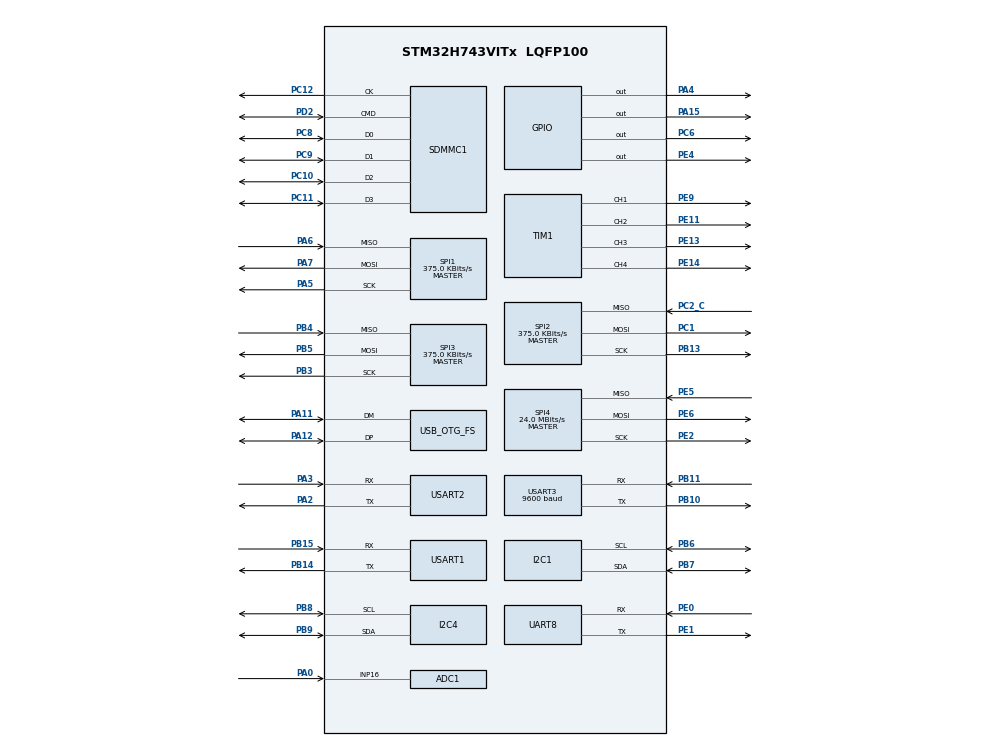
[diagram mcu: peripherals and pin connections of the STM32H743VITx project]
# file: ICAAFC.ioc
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ADC1.Channel-0\#ChannelRegularConversion=ADC_CHANNEL_16
ADC1.ContinuousConvMode=ENABLE
ADC1.ConversionDataManagement=ADC_CONVERSIONDATA_DMA_CIRCULAR
ADC1.NbrOfConversionFlag=1
ADC1.OffsetNumber-0\#ChannelRegularConversion=ADC_OFFSET_NONE
ADC1.OffsetSignedSaturation-0\#ChannelRegularConversion=DISABLE
ADC1.Rank-0\#ChannelRegularConversion=1
ADC1.SamplingTime-0\#ChannelRegularConversion=ADC_SAMPLETIME_32CYCLES_5
ADC1.master=1
CORTEX_M7.default_mode_Activation=1
Dma.ADC1.0.Direction=DMA_PERIPH_TO_MEMORY
Dma.ADC1.0.EventEnable=DISABLE
Dma.ADC1.0.FIFOMode=DMA_FIFOMODE_DISABLE
Dma.ADC1.0.Instance=DMA1_Stream0
Dma.ADC1.0.MemDataAlignment=DMA_MDATAALIGN_HALFWORD
Dma.ADC1.0.MemInc=DMA_MINC_ENABLE
Dma.ADC1.0.Mode=DMA_CIRCULAR
Dma.ADC1.0.PeriphDataAlignment=DMA_PDATAALIGN_HALFWORD
Dma.ADC1.0.PeriphInc=DMA_PINC_DISABLE
Dma.ADC1.0.Polarity=HAL_DMAMUX_REQ_GEN_RISING
Dma.ADC1.0.Priority=DMA_PRIORITY_LOW
Dma.ADC1.0.RequestNumber=1
Dma.ADC1.0.SignalID=NONE
Dma.ADC1.0.SyncEnable=DISABLE
Dma.ADC1.0.SyncPolarity=HAL_DMAMUX_SYNC_NO_EVENT
Dma.ADC1.0.SyncRequestNumber=1
Dma.ADC1.0.SyncSignalID=NONE
Dma.Request0=ADC1
FREERTOS.Tasks01=HeartTask,24,256,AppHeartTask,Default,NULL,Dynamic,NULL,NULL;CommunicateTask,8,256,AppCommunicateTask02,Default,NULL,Dynamic,NULL,NULL;ControllerTask,8,256,AppControllerTask,Default,NULL,Dynamic,NULL,NULL;NavigationTask,8,256,AppNavigationTask,Default,NULL,Dynamic,NULL,NULL;EstimatorTask,8,256,AppEstimatorTask,Default,NULL,Dynamic,NULL,NULL
I2C1.Timing=0x20303E5D
I2C4.Timing=0x20303E5D
Mcu.Family=STM32H7
Mcu.Name=STM32H743VITx
Mcu.Package=LQFP100
NVIC.DMA1_Stream0_IRQn=true\:5\:0\:false\:false\:true\:true\:false\:true\:true
NVIC.PriorityGroup=NVIC_PRIORITYGROUP_4
NVIC.TIM6_DAC_IRQn=true\:15\:0\:false\:false\:true\:false\:false\:true\:true
NVIC.TimeBase=TIM6_DAC_IRQn
NVIC.TimeBaseIP=TIM6
NVIC.USART2_IRQn=true\:5\:0\:false\:false\:true\:true\:true\:true\:true
NVIC.USART3_IRQn=true\:5\:0\:false\:false\:true\:true\:true\:true\:true
PA0.Mode=IN16-Single-Ended
PA0.Signal=ADC1_INP16
PA11.Mode=Device_Only
PA11.Signal=USB_OTG_FS_DM
PA12.Mode=Device_Only
PA12.Signal=USB_OTG_FS_DP
PA13\ (JTMS/SWDIO).Mode=Serial_Wire
PA13\ (JTMS/SWDIO).Signal=DEBUG_JTMS-SWDIO
PA14\ (JTCK/SWCLK).Mode=Serial_Wire
PA14\ (JTCK/SWCLK).Signal=DEBUG_JTCK-SWCLK
PA15\ (JTDI).Signal=GPIO_Output
PA2.Mode=Asynchronous
PA2.Signal=USART2_TX
PA3.Mode=Asynchronous
PA3.Signal=USART2_RX
PA4.Signal=GPIO_Output
PA5.Mode=Full_Duplex_Master
PA5.Signal=SPI1_SCK
PA6.Mode=Full_Duplex_Master
PA6.Signal=SPI1_MISO
PA7.Mode=Full_Duplex_Master
PA7.Signal=SPI1_MOSI
PB10.Mode=Asynchronous
PB10.Signal=USART3_TX
PB11.Mode=Asynchronous
PB11.Signal=USART3_RX
PB13.Mode=Full_Duplex_Master
PB13.Signal=SPI2_SCK
PB14.Mode=Asynchronous
PB14.Signal=USART1_TX
PB15.Mode=Asynchronous
PB15.Signal=USART1_RX
PB3\ (JTDO/TRACESWO).Mode=Full_Duplex_Master
PB3\ (JTDO/TRACESWO).Signal=SPI3_SCK
PB4\ (NJTRST).Mode=Full_Duplex_Master
PB4\ (NJTRST).Signal=SPI3_MISO
PB5.Mode=Full_Duplex_Master
PB5.Signal=SPI3_MOSI
PB6.Mode=I2C
PB6.Signal=I2C1_SCL
PB7.Mode=I2C
PB7.Signal=I2C1_SDA
PB8.Mode=I2C
PB8.Signal=I2C4_SCL
PB9.Mode=I2C
PB9.Signal=I2C4_SDA
PC1.Mode=Full_Duplex_Master
PC1.Signal=SPI2_MOSI
PC10.Mode=SD_4_bits_Wide_bus
PC10.Signal=SDMMC1_D2
PC11.Mode=SD_4_bits_Wide_bus
PC11.Signal=SDMMC1_D3
PC12.Mode=SD_4_bits_Wide_bus
PC12.Signal=SDMMC1_CK
PC2_C.Mode=Full_Duplex_Master
PC2_C.Signal=SPI2_MISO
PC6.Signal=GPIO_Output
PC8.Mode=SD_4_bits_Wide_bus
PC8.Signal=SDMMC1_D0
PC9.Mode=SD_4_bits_Wide_bus
PC9.Signal=SDMMC1_D1
PD2.Mode=SD_4_bits_Wide_bus
PD2.Signal=SDMMC1_CMD
PE0.Mode=Asynchronous
PE0.Signal=UART8_RX
PE1.Mode=Asynchronous
PE1.Signal=UART8_TX
PE11.Signal=S_TIM1_CH2
PE13.Signal=S_TIM1_CH3
PE14.Signal=S_TIM1_CH4
PE2.Mode=Full_Duplex_Master
PE2.Signal=SPI4_SCK
PE4.Signal=GPIO_Output
PE5.Mode=Full_Duplex_Master
PE5.Signal=SPI4_MISO
PE6.Mode=Full_Duplex_Master
PE6.Signal=SPI4_MOSI
PE9.Signal=S_TIM1_CH1
PH0-OSC_IN\ (PH0).Mode=HSE-External-Oscillator
PH0-OSC_IN\ (PH0).Signal=RCC_OSC_IN
PH1-OSC_OUT\ (PH1).Mode=HSE-External-Oscillator
PH1-OSC_OUT\ (PH1).Signal=RCC_OSC_OUT
ProjectManager.HeapSize=0x200
ProjectManager.StackSize=0x400
ProjectManager.TargetToolchain=MDK-ARM V5.32
RCC.ADCFreq_Value=75000000
RCC.APB1Freq_Value=48000000
RCC.APB2Freq_Value=48000000
RCC.APB3Freq_Value=96000000
RCC.APB4Freq_Value=48000000
RCC.CortexFreq_Value=96000000
RCC.D2PPRE1=RCC_APB1_DIV2
RCC.D2PPRE2=RCC_APB2_DIV2
RCC.D3PPRE=RCC_APB4_DIV2
RCC.DIVM1=1
RCC.DIVM2=1
RCC.DIVN1=24
RCC.DIVN2=18
RCC.DIVQ1=4
RCC.HCLKFreq_Value=96000000
RCC.HSE_VALUE=8000000
RCC.PLL2FRACN=6144
RCC.PLL3FRACN=0
RCC.PLLFRACN=0
RCC.PLLSourceVirtual=RCC_PLLSOURCE_HSE
RCC.SYSCLKFreq_VALUE=96000000
RCC.SYSCLKSource=RCC_SYSCLKSOURCE_PLLCLK
RCC.USBFreq_Value=48000000
SH.S_TIM1_CH1.0=TIM1_CH1,PWM Generation1 CH1
SH.S_TIM1_CH2.0=TIM1_CH2,PWM Generation2 CH2
SH.S_TIM1_CH3.0=TIM1_CH3,PWM Generation3 CH3
SH.S_TIM1_CH4.0=TIM1_CH4,PWM Generation4 CH4
SPI1.BaudRatePrescaler=SPI_BAUDRATEPRESCALER_128
SPI1.CalculateBaudRate=375.0 KBits/s
SPI1.Direction=SPI_DIRECTION_2LINES
SPI1.Mode=SPI_MODE_MASTER
SPI1.VirtualType=VM_MASTER
SPI2.BaudRatePrescaler=SPI_BAUDRATEPRESCALER_128
SPI2.CalculateBaudRate=375.0 KBits/s
SPI2.Direction=SPI_DIRECTION_2LINES
SPI2.Mode=SPI_MODE_MASTER
SPI2.VirtualType=VM_MASTER
SPI3.BaudRatePrescaler=SPI_BAUDRATEPRESCALER_128
SPI3.CalculateBaudRate=375.0 KBits/s
SPI3.Direction=SPI_DIRECTION_2LINES
SPI3.Mode=SPI_MODE_MASTER
SPI3.VirtualType=VM_MASTER
SPI4.CalculateBaudRate=24.0 MBits/s
SPI4.Direction=SPI_DIRECTION_2LINES
SPI4.Mode=SPI_MODE_MASTER
SPI4.VirtualType=VM_MASTER
TIM1.Channel-PWM\ Generation1\ CH1=TIM_CHANNEL_1
TIM1.Channel-PWM\ Generation2\ CH2=TIM_CHANNEL_2
TIM1.Channel-PWM\ Generation3\ CH3=TIM_CHANNEL_3
TIM1.Channel-PWM\ Generation4\ CH4=TIM_CHANNEL_4
USART1.VirtualMode-Asynchronous=VM_ASYNC
USART2.VirtualMode-Asynchronous=VM_ASYNC
USART3.BaudRate=9600
USART3.VirtualMode-Asynchronous=VM_ASYNC
USB_OTG_FS.VirtualMode=Device_Only
VP_FREERTOS_VS_CMSIS_V2.Mode=CMSIS_V2
VP_SYS_VS_tim6.Mode=TIM6
VP_TIM1_VS_ClockSourceINT.Mode=Internal
board=custom

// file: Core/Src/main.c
/* USER CODE BEGIN Header */
/**
  ******************************************************************************
  * @file           : main.c
  * @brief          : Main program body
  ******************************************************************************
  * @attention
  *
  * Copyright (c) 2025 STMicroelectronics.
  * All rights reserved.
  *
  * This software is licensed under terms that can be found in the LICENSE file
  * in the root directory of this software component.
  * If no LICENSE file comes with this software, it is provided AS-IS.
  *
  ******************************************************************************
  */
/* USER CODE END Header */
#include "main.h"
#include "cmsis_os.h"
#include "adc.h"
#include "dma.h"
#include "i2c.h"
#include "sdmmc.h"
#include "spi.h"
#include "tim.h"
#include "usart.h"
#include "usb_otg.h"
#include "gpio.h"

void SystemClock_Config(void);
static void MPU_Config(void);
void MX_FREERTOS_Init(void);

int main(void)
{

  /* MPU Configuration--------------------------------------------------------*/
  MPU_Config();

  /* MCU Configuration--------------------------------------------------------*/

  /* Reset of all peripherals, Initializes the Flash interface and the Systick. */
  HAL_Init();

  /* Configure the system clock */
  SystemClock_Config();

  /* Initialize all configured peripherals */
  MX_GPIO_Init();
  MX_DMA_Init();
  MX_ADC1_Init();
  MX_I2C1_Init();
  MX_I2C4_Init();
  MX_SDMMC1_SD_Init();
  MX_SPI1_Init();
  MX_SPI2_Init();
  MX_SPI3_Init();
  MX_SPI4_Init();
  MX_TIM1_Init();
  MX_UART8_Init();
  MX_USART1_UART_Init();
  MX_USART2_UART_Init();
  MX_USART3_UART_Init();
  MX_USB_OTG_FS_PCD_Init();
  /* USER CODE BEGIN 2 */
/*ujik */
  /* USER CODE END 2 */

  /* Init scheduler */
  osKernelInitialize();

  /* Call init function for freertos objects (in cmsis_os2.c) */
  MX_FREERTOS_Init();

  /* Start scheduler */
  osKernelStart();

  /* We should never get here as control is now taken by the scheduler */

  /* Infinite loop */
  while (1)
  {

  }
}

void SystemClock_Config(void)
{
  RCC_OscInitTypeDef RCC_OscInitStruct = {0};
  RCC_ClkInitTypeDef RCC_ClkInitStruct = {0};

  /** Supply configuration update enable
  */
  HAL_PWREx_ConfigSupply(PWR_LDO_SUPPLY);

  /** Configure the main internal regulator output voltage
  */
  __HAL_PWR_VOLTAGESCALING_CONFIG(PWR_REGULATOR_VOLTAGE_SCALE3);

  while(!__HAL_PWR_GET_FLAG(PWR_FLAG_VOSRDY)) {}

  /** Initializes the RCC Oscillators according to the specified parameters
  * in the RCC_OscInitTypeDef structure.
  */
  RCC_OscInitStruct.OscillatorType = RCC_OSCILLATORTYPE_HSE;
  RCC_OscInitStruct.HSEState = RCC_HSE_ON;
  RCC_OscInitStruct.PLL.PLLState = RCC_PLL_ON;
  RCC_OscInitStruct.PLL.PLLSource = RCC_PLLSOURCE_HSE;
  RCC_OscInitStruct.PLL.PLLM = 1;
  RCC_OscInitStruct.PLL.PLLN = 24;
  RCC_OscInitStruct.PLL.PLLP = 2;
  RCC_OscInitStruct.PLL.PLLQ = 4;
  RCC_OscInitStruct.PLL.PLLR = 2;
  RCC_OscInitStruct.PLL.PLLRGE = RCC_PLL1VCIRANGE_3;
  RCC_OscInitStruct.PLL.PLLVCOSEL = RCC_PLL1VCOWIDE;
  RCC_OscInitStruct.PLL.PLLFRACN = 0;
  if (HAL_RCC_OscConfig(&RCC_OscInitStruct) != HAL_OK)
  {
    Error_Handler();
  }

  /** Initializes the CPU, AHB and APB buses clocks
  */
  RCC_ClkInitStruct.ClockType = RCC_CLOCKTYPE_HCLK|RCC_CLOCKTYPE_SYSCLK
                              |RCC_CLOCKTYPE_PCLK1|RCC_CLOCKTYPE_PCLK2
                              |RCC_CLOCKTYPE_D3PCLK1|RCC_CLOCKTYPE_D1PCLK1;
  RCC_ClkInitStruct.SYSCLKSource = RCC_SYSCLKSOURCE_PLLCLK;
  RCC_ClkInitStruct.SYSCLKDivider = RCC_SYSCLK_DIV1;
  RCC_ClkInitStruct.AHBCLKDivider = RCC_HCLK_DIV1;
  RCC_ClkInitStruct.APB3CLKDivider = RCC_APB3_DIV1;
  RCC_ClkInitStruct.APB1CLKDivider = RCC_APB1_DIV2;
  RCC_ClkInitStruct.APB2CLKDivider = RCC_APB2_DIV2;
  RCC_ClkInitStruct.APB4CLKDivider = RCC_APB4_DIV2;

  if (HAL_RCC_ClockConfig(&RCC_ClkInitStruct, FLASH_LATENCY_2) != HAL_OK)
  {
    Error_Handler();
  }
}

 /* MPU Configuration */

void MPU_Config(void)
{
  MPU_Region_InitTypeDef MPU_InitStruct = {0};

  /* Disables the MPU */
  HAL_MPU_Disable();

  /** Initializes and configures the Region and the memory to be protected
  */
  MPU_InitStruct.Enable = MPU_REGION_ENABLE;
  MPU_InitStruct.Number = MPU_REGION_NUMBER0;
  MPU_InitStruct.BaseAddress = 0x0;
  MPU_InitStruct.Size = MPU_REGION_SIZE_4GB;
  MPU_InitStruct.SubRegionDisable = 0x87;
  MPU_InitStruct.TypeExtField = MPU_TEX_LEVEL0;
  MPU_InitStruct.AccessPermission = MPU_REGION_NO_ACCESS;
  MPU_InitStruct.DisableExec = MPU_INSTRUCTION_ACCESS_DISABLE;
  MPU_InitStruct.IsShareable = MPU_ACCESS_SHAREABLE;
  MPU_InitStruct.IsCacheable = MPU_ACCESS_NOT_CACHEABLE;
  MPU_InitStruct.IsBufferable = MPU_ACCESS_NOT_BUFFERABLE;

  HAL_MPU_ConfigRegion(&MPU_InitStruct);
  /* Enables the MPU */
  HAL_MPU_Enable(MPU_PRIVILEGED_DEFAULT);

}

void HAL_TIM_PeriodElapsedCallback(TIM_HandleTypeDef *htim)
{
  if (htim->Instance == TIM6) {
    HAL_IncTick();
  }
}

void Error_Handler(void)
{
  __disable_irq();
  while (1)
  {
  }
}

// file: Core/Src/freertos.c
/* USER CODE BEGIN Header */
/**
  ******************************************************************************
  * File Name          : freertos.c
  * Description        : Code for freertos applications
  ******************************************************************************
  * @attention
  *
  * Copyright (c) 2025 STMicroelectronics.
  * All rights reserved.
  *
  * This software is licensed under terms that can be found in the LICENSE file
  * in the root directory of this software component.
  * If no LICENSE file comes with this software, it is provided AS-IS.
  *
  ******************************************************************************
  */
/* USER CODE END Header */

#include "FreeRTOS.h"
#include "task.h"
#include "main.h"
#include "cmsis_os.h"

/* Definitions for HeartTask */
osThreadId_t HeartTaskHandle;
const osThreadAttr_t HeartTask_attributes = {
  .name = "HeartTask",
  .stack_size = 256 * 4,
  .priority = (osPriority_t) osPriorityNormal,
};
/* Definitions for CommunicateTask */
osThreadId_t CommunicateTaskHandle;
const osThreadAttr_t CommunicateTask_attributes = {
  .name = "CommunicateTask",
  .stack_size = 256 * 4,
  .priority = (osPriority_t) osPriorityLow,
};
/* Definitions for ControllerTask */
osThreadId_t ControllerTaskHandle;
const osThreadAttr_t ControllerTask_attributes = {
  .name = "ControllerTask",
  .stack_size = 256 * 4,
  .priority = (osPriority_t) osPriorityLow,
};
/* Definitions for NavigationTask */
osThreadId_t NavigationTaskHandle;
const osThreadAttr_t NavigationTask_attributes = {
  .name = "NavigationTask",
  .stack_size = 256 * 4,
  .priority = (osPriority_t) osPriorityLow,
};
/* Definitions for EstimatorTask */
osThreadId_t EstimatorTaskHandle;
const osThreadAttr_t EstimatorTask_attributes = {
  .name = "EstimatorTask",
  .stack_size = 256 * 4,
  .priority = (osPriority_t) osPriorityLow,
};

void AppHeartTask(void *argument);
void AppCommunicateTask02(void *argument);
void AppControllerTask(void *argument);
void AppNavigationTask(void *argument);
void AppEstimatorTask(void *argument);

void MX_FREERTOS_Init(void); /* (MISRA C 2004 rule 8.1) */

void MX_FREERTOS_Init(void) {

  /* Create the thread(s) */
  /* creation of HeartTask */
  HeartTaskHandle = osThreadNew(AppHeartTask, NULL, &HeartTask_attributes);

  /* creation of CommunicateTask */
  CommunicateTaskHandle = osThreadNew(AppCommunicateTask02, NULL, &CommunicateTask_attributes);

  /* creation of ControllerTask */
  ControllerTaskHandle = osThreadNew(AppControllerTask, NULL, &ControllerTask_attributes);

  /* creation of NavigationTask */
  NavigationTaskHandle = osThreadNew(AppNavigationTask, NULL, &NavigationTask_attributes);

  /* creation of EstimatorTask */
  EstimatorTaskHandle = osThreadNew(AppEstimatorTask, NULL, &EstimatorTask_attributes);

}

void AppHeartTask(void *argument)
{
  for(;;)
  {
    osDelay(1);
  }
}

void AppCommunicateTask02(void *argument)
{
  for(;;)
  {
    osDelay(1);
  }
}

void AppControllerTask(void *argument)
{
  for(;;)
  {
    osDelay(1);
  }
}

void AppNavigationTask(void *argument)
{
  for(;;)
  {
    osDelay(1);
  }
}

void AppEstimatorTask(void *argument)
{
  for(;;)
  {
    osDelay(1);
  }
}
